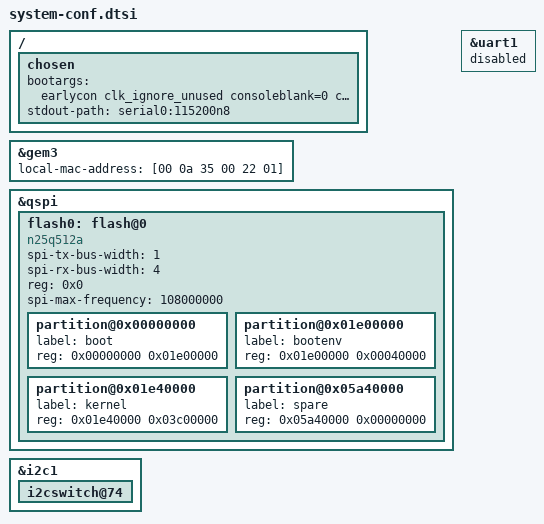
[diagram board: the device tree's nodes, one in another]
/ {
	chosen {
		bootargs = "earlycon clk_ignore_unused consoleblank=0 cma=1700M uio_pdrv_genirq.of_id=generic-uio";
		stdout-path = "serial0:115200n8";
	};
};

&gem3 {
	local-mac-address = [00 0a 35 00 22 01];
};

&qspi {
	#address-cells = <1>;
	#size-cells = <0>;
	flash0: flash@0 {
		compatible = "n25q512a","micron,m25p80";
		spi-tx-bus-width=<1>;
		spi-rx-bus-width=<4>;
		reg = <0x0>;
		#address-cells = <1>;
		#size-cells = <1>;
		spi-max-frequency = <108000000>;
		/delete-node/ partition@qspi-fsbl-uboot;
		/delete-node/ partition@qspi-linux;
		/delete-node/ partition@qspi-device-tree;
		/delete-node/ partition@qspi-rootfs;
		/delete-node/ partition@qspi-bitstream;
		partition@0x00000000 {
			label = "boot";
			reg = <0x00000000 0x01e00000>;
		};
		partition@0x01e00000 {
			label = "bootenv";
			reg = <0x01e00000 0x00040000>;
		};
		partition@0x01e40000 {
			label = "kernel";
			reg = <0x01e40000 0x03c00000>;
		};
		partition@0x05a40000 {
			label = "spare";
			reg = <0x05a40000 0x00000000>;
		};
	};
};

&i2c1 {
	i2cswitch@74 {
	/delete-node/ 	i2c@2;
	};
};

&uart1 {
    status = "disabled";
};
